# STM32WL3R register map
File version: 1.0
CPU: CM0+ r0p0, little endian, MPU, no FPU, 4 interrupt priority bits
Registers are 32-bit, read-write, reset 0x0 unless marked. A register's access mark holds for its fields unless they carry their own. Offsets are from the block's base; [hi:lo] are bit positions; {n}, {i} and the like mark numbered series; 'fields as' and 'values as' point back to an identical list.

## CRC — CRC address block description
Base 0x48200000
0x00 CRC_DR reset 0xFFFFFFFF
  [31:0] DR — Data register bits.
0x04 CRC_IDR
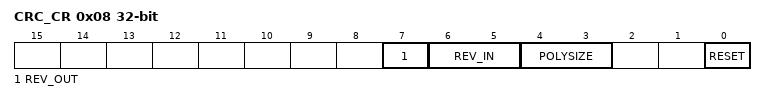
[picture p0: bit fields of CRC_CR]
0x08 CRC_CR
  [7] REV_OUT — Reverse output data
  [6:5] REV_IN — Reverse input data
  [4:3] POLYSIZE — Polynomial size
  [0] RESET — RESET bit
0x10 CRC_INIT reset 0xFFFFFFFF
  [31:0] INIT — Programmable initial CRC value
0x14 CRC_POL reset 0x4C11DB7
  [31:0] POL — POL[31:0]: Programmable polynomial

## DBGMCU — DBGMCU address block description
Base 0x40008000
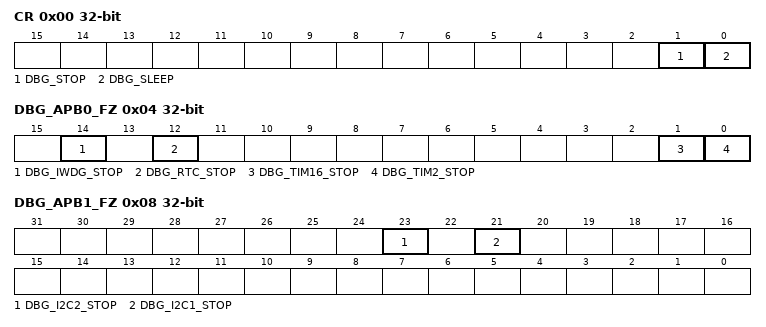
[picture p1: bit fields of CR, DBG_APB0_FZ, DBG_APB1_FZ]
0x00 CR
  [1] DBG_STOP — Allow debug of the CPU in DEEPSTOP mode
  [0] DBG_SLEEP — Allow debug of the CPU in SLEEP mode
0x04 DBG_APB0_FZ
  [14] DBG_IWDG_STOP — IWDG stop in the CPU debug
  [12] DBG_RTC_STOP — RTC stop in CPU debug
  [1] DBG_TIM16_STOP — TIM16 stop in the CPU debug
  [0] DBG_TIM2_STOP — TIM2 stop in the CPU debug
0x08 DBG_APB1_FZ
  [23] DBG_I2C2_STOP — I2C2 SMBUS timeout stop in CPU debug
  [21] DBG_I2C1_STOP — I2C1 SMBUS timeout stop in CPU debug

## DMAMUX — DMAMUX address block description
Base 0x48800000
{0x0+4i} C{i}CR (reset mask 0xF) (i=0..7) — CxCR register
  [4:0] DMAREQ_ID — DMAREQ_ID[4:0]: DMA REQuest IDentification

## DMA — DMA address block description
Base 0x48700000
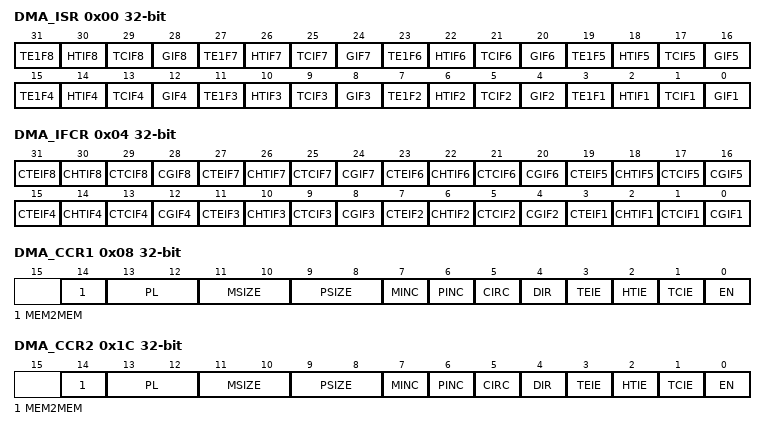
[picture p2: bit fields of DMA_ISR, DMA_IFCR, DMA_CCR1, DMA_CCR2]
0x00 DMA_ISR ro (reset mask 0xFFFF)
  [4n-1] TE1F{n} (n=1..8) — TEIF{n}: Channel {n} transfer error flag This bit is set by hardware.
  [4n-2] HTIF{n} (n=1..8) — HTIF{n}: Channel {n} half transfer flag
  [4n-3] TCIF{n} (n=1..8) — TCIF{n}: Channel {n} transfer complete flag
  [4n-4] GIF{n} (n=1..8) — GIF{n}: Channel {n} global interrupt flag
0x04 DMA_IFCR wo (reset mask 0xFFFF)
  [4n-1] CTEIF{n} (n=1..8) — CTEIF{n}: Channel {n} transfer error clear
  [4n-2] CHTIF{n} (n=1..8) — CHTIF{n}: Channel {n} half transfer clear
  [4n-3] CTCIF{n} (n=1..8) — CTCIF{n}: Channel {n} transfer complete clear
  [4n-4] CGIF{n} (n=1..8) — CGIF{n}: Channel {n} global interrupt clear
0x08 DMA_CCR1 — DMA_CCRx register
  [14] MEM2MEM — MEM2MEM: Memory to memory mode
  [13:12] PL — PL[1:0]: Channel priority level
  [11:10] MSIZE — MSIZE[1:0]: Memory size
  [9:8] PSIZE — PSIZE[1:0]: Peripheral size
  [7] MINC — MINC: Memory increment mode
  [6] PINC — PINC: Peripheral increment mode
  [5] CIRC — CIRC: Circular mode
  [4] DIR — DIR: Data transfer direction
  [3] TEIE — TEIE: Transfer error interrupt enable
  [2] HTIE — HTIE: Half transfer interrupt enable
  [1] TCIE — TCIE: Transfer complete interrupt enable
  [0] EN — EN: Channel enable
0x0C DMA_CNDTR1 (reset mask 0xF) — DMA_CNDTRx register
  [15:0] NDT — NDT[15:0]: Number of data to transfer
0x10 DMA_CPAR1 (reset mask 0xF) — DMA_CPARx register
  [31:0] PA — PA[31:0]: Peripheral address
{0x0+0x14*i} DMA_CMAR{i} (reset mask 0xF) (i=1..8) — DMA_CMARx register
  [31:0] MA — MA[31:0]: Memory address
0x1C DMA_CCR2 — DMA_CCRx register
  fields as DMA_CCR1
0x20 DMA_CNDTR2 (reset mask 0xF) — DMA_CNDTRx register
  [15:0] NDT — NDT[15:0]: Number of data to transfer
0x24 DMA_CPAR2 (reset mask 0xF) — DMA_CPARx register
  [31:0] PA — PA[31:0]: Peripheral address
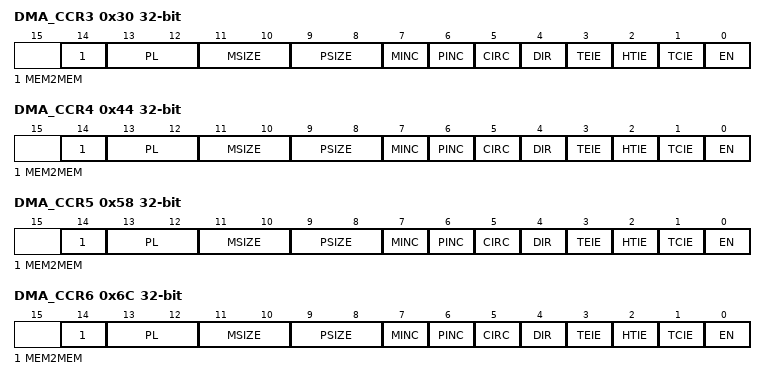
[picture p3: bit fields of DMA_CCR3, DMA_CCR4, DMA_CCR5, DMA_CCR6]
0x30 DMA_CCR3 — DMA_CCRx register
  fields as DMA_CCR1
0x34 DMA_CNDTR3 (reset mask 0xF) — DMA_CNDTRx register
  [15:0] NDT — NDT[15:0]: Number of data to transfer
0x38 DMA_CPAR3 (reset mask 0xF) — DMA_CPARx register
  [31:0] PA — PA[31:0]: Peripheral address
0x44 DMA_CCR4 — DMA_CCRx register
  fields as DMA_CCR1
0x48 DMA_CNDTR4 (reset mask 0xF) — DMA_CNDTRx register
  [15:0] NDT — NDT[15:0]: Number of data to transfer
0x4C DMA_CPAR4 (reset mask 0xF) — DMA_CPARx register
  [31:0] PA — PA[31:0]: Peripheral address
0x58 DMA_CCR5 — DMA_CCRx register
  fields as DMA_CCR1
0x5C DMA_CNDTR5 (reset mask 0xF) — DMA_CNDTRx register
  [15:0] NDT — NDT[15:0]: Number of data to transfer
0x60 DMA_CPAR5 (reset mask 0xF) — DMA_CPARx register
  [31:0] PA — PA[31:0]: Peripheral address
0x6C DMA_CCR6 — DMA_CCRx register
  fields as DMA_CCR1
0x70 DMA_CNDTR6 (reset mask 0xF) — DMA_CNDTRx register
  [15:0] NDT — NDT[15:0]: Number of data to transfer
0x74 DMA_CPAR6 (reset mask 0xF) — DMA_CPARx register
  [31:0] PA — PA[31:0]: Peripheral address
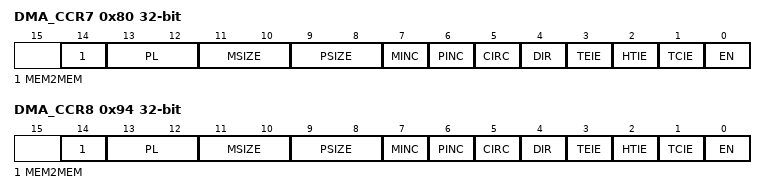
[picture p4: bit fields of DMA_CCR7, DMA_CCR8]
0x80 DMA_CCR7 — DMA_CCRx register
  fields as DMA_CCR1
0x84 DMA_CNDTR7 (reset mask 0xF) — DMA_CNDTRx register
  [15:0] NDT — NDT[15:0]: Number of data to transfer
0x88 DMA_CPAR7 (reset mask 0xF) — DMA_CPARx register
  [31:0] PA — PA[31:0]: Peripheral address
0x94 DMA_CCR8 — DMA_CCRx register
  fields as DMA_CCR1
0x98 DMA_CNDTR8 (reset mask 0xF) — DMA_CNDTRx register
  [15:0] NDT — NDT[15:0]: Number of data to transfer
0x9C DMA_CPAR8 (reset mask 0xF) — DMA_CPARx register
  [31:0] PA — PA[31:0]: Peripheral address

## Notices in the file
Copyright (c) 2025 STMicroelectronics.
SPDX-License-Identifier: Apache-2.0
Licensed under the Apache License, Version 2.0 (the "License");
you may not use this file except in compliance with the License.
You may obtain a copy of the License at
http://www.apache.org/licenses/LICENSE-2.0
Unless required by applicable law or agreed to in writing, software
distributed under the License is distributed on an "AS IS" BASIS,
WITHOUT WARRANTIES OR CONDITIONS OF ANY KIND, either express or implied.
See the License for the specific language governing permissions and
limitations under the License.
